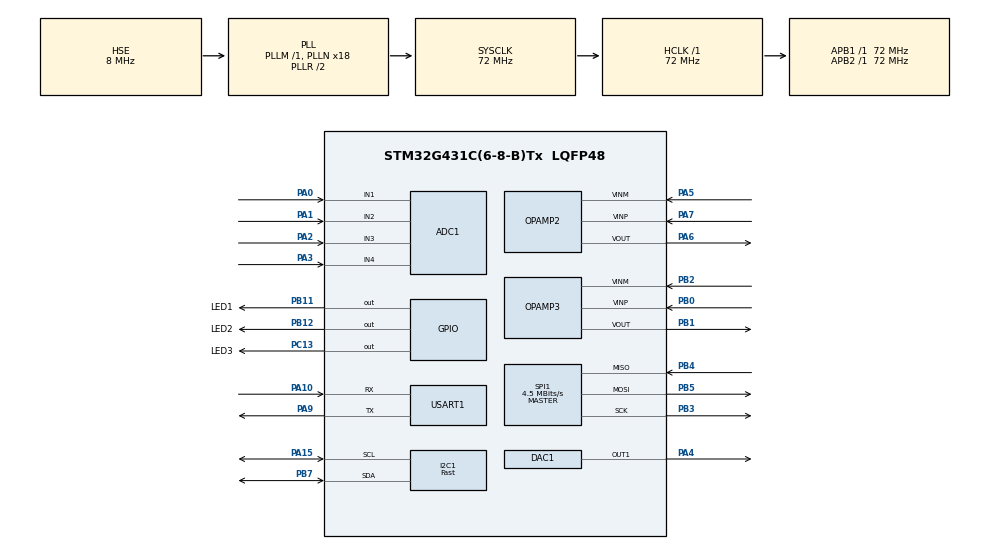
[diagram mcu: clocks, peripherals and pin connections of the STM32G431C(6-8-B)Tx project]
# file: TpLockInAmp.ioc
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ADC1.Channel-22\#ChannelRegularConversion=ADC_CHANNEL_2
ADC1.Channel-23\#ChannelRegularConversion=ADC_CHANNEL_3
ADC1.Channel-24\#ChannelRegularConversion=ADC_CHANNEL_4
ADC1.Channel-5\#ChannelRegularConversion=ADC_CHANNEL_1
ADC1.ClockPrescaler=ADC_CLOCK_ASYNC_DIV6
ADC1.ContinuousConvMode=DISABLE
ADC1.DMAContinuousRequests=ENABLE
ADC1.DiscontinuousConvMode=DISABLE
ADC1.EOCSelection=ADC_EOC_SINGLE_CONV
ADC1.ExternalTrigConv=ADC_EXTERNALTRIG_T2_TRGO
ADC1.ExternalTrigConvEdge=ADC_EXTERNALTRIGCONVEDGE_RISING
ADC1.NbrOfConversion=4
ADC1.NbrOfConversionFlag=1
ADC1.OffsetNumber-22\#ChannelRegularConversion=ADC_OFFSET_NONE
ADC1.OffsetNumber-23\#ChannelRegularConversion=ADC_OFFSET_NONE
ADC1.OffsetNumber-24\#ChannelRegularConversion=ADC_OFFSET_NONE
ADC1.OffsetNumber-5\#ChannelRegularConversion=ADC_OFFSET_NONE
ADC1.Rank-22\#ChannelRegularConversion=2
ADC1.Rank-23\#ChannelRegularConversion=3
ADC1.Rank-24\#ChannelRegularConversion=4
ADC1.Rank-5\#ChannelRegularConversion=1
ADC1.SamplingTime-22\#ChannelRegularConversion=ADC_SAMPLETIME_2CYCLES_5
ADC1.SamplingTime-23\#ChannelRegularConversion=ADC_SAMPLETIME_2CYCLES_5
ADC1.SamplingTime-24\#ChannelRegularConversion=ADC_SAMPLETIME_2CYCLES_5
ADC1.SamplingTime-5\#ChannelRegularConversion=ADC_SAMPLETIME_2CYCLES_5
ADC1.master=1
Dma.ADC1.0.Direction=DMA_PERIPH_TO_MEMORY
Dma.ADC1.0.EventEnable=DISABLE
Dma.ADC1.0.Instance=DMA1_Channel1
Dma.ADC1.0.MemDataAlignment=DMA_MDATAALIGN_HALFWORD
Dma.ADC1.0.MemInc=DMA_MINC_ENABLE
Dma.ADC1.0.Mode=DMA_CIRCULAR
Dma.ADC1.0.PeriphDataAlignment=DMA_PDATAALIGN_HALFWORD
Dma.ADC1.0.PeriphInc=DMA_PINC_DISABLE
Dma.ADC1.0.Polarity=HAL_DMAMUX_REQ_GEN_RISING
Dma.ADC1.0.Priority=DMA_PRIORITY_LOW
Dma.ADC1.0.RequestNumber=1
Dma.ADC1.0.SignalID=NONE
Dma.ADC1.0.SyncEnable=DISABLE
Dma.ADC1.0.SyncPolarity=HAL_DMAMUX_SYNC_NO_EVENT
Dma.ADC1.0.SyncRequestNumber=1
Dma.ADC1.0.SyncSignalID=NONE
Dma.Request0=ADC1
I2C1.I2C_Speed_Mode=I2C_Fast
I2C1.Timing=0x00702681
Mcu.Family=STM32G4
Mcu.Name=STM32G431C(6-8-B)Tx
Mcu.Package=LQFP48
NVIC.DMA1_Channel1_IRQn=true\:0\:0\:false\:false\:true\:false\:true
NVIC.PriorityGroup=NVIC_PRIORITYGROUP_4
NVIC.TIM2_IRQn=true\:0\:0\:false\:false\:true\:true\:true
NVIC.TIM6_DAC_IRQn=true\:0\:0\:false\:false\:true\:true\:true
NVIC.TIM7_IRQn=true\:0\:0\:false\:false\:true\:true\:true
NVIC.USART1_IRQn=true\:0\:0\:false\:false\:true\:true\:true
OPAMP2.PowerMode=OPAMP_POWERMODE_NORMALSPEED
OPAMP3.PowerMode=OPAMP_POWERMODE_NORMALSPEED
PA0.Mode=IN1-Single-Ended
PA0.Signal=ADC1_IN1
PA1.Mode=IN2-Single-Ended
PA1.Signal=ADC1_IN2
PA10.Mode=Asynchronous
PA10.Signal=USART1_RX
PA13.Mode=Serial_Wire
PA13.Signal=SYS_JTMS-SWDIO
PA14.Mode=Serial_Wire
PA14.Signal=SYS_JTCK-SWCLK
PA15.Mode=I2C
PA15.Signal=I2C1_SCL
PA2.Mode=IN3-Single-Ended
PA2.Signal=ADC1_IN3
PA3.Mode=IN4-Single-Ended
PA3.Signal=ADC1_IN4
PA4.Signal=COMP_DAC11_group
PA5.Mode=Standalone
PA5.Signal=OPAMP2_VINM
PA6.Mode=Standalone
PA6.Signal=OPAMP2_VOUT
PA7.Mode=Standalone
PA7.Signal=OPAMP2_VINP
PA9.Mode=Asynchronous
PA9.Signal=USART1_TX
PB0.Mode=Standalone
PB0.Signal=OPAMP3_VINP
PB1.Mode=Standalone
PB1.Signal=OPAMP3_VOUT
PB11.GPIO_Label=LED1
PB11.GPIO_PuPd=GPIO_PULLDOWN
PB11.PinState=GPIO_PIN_SET
PB11.Signal=GPIO_Output
PB12.GPIO_Label=LED2
PB12.GPIO_PuPd=GPIO_PULLDOWN
PB12.PinState=GPIO_PIN_SET
PB12.Signal=GPIO_Output
PB2.Mode=Standalone
PB2.Signal=OPAMP3_VINM
PB3.Mode=Full_Duplex_Master
PB3.Signal=SPI1_SCK
PB4.Mode=Full_Duplex_Master
PB4.Signal=SPI1_MISO
PB5.Mode=Full_Duplex_Master
PB5.Signal=SPI1_MOSI
PB7.Mode=I2C
PB7.Signal=I2C1_SDA
PC13.GPIO_Label=LED3
PC13.PinState=GPIO_PIN_SET
PC13.Signal=GPIO_Output
PF0-OSC_IN.Mode=HSE-External-Oscillator
PF0-OSC_IN.Signal=RCC_OSC_IN
PF1-OSC_OUT.Mode=HSE-External-Oscillator
PF1-OSC_OUT.Signal=RCC_OSC_OUT
ProjectManager.HeapSize=0x200
ProjectManager.StackSize=0x400
ProjectManager.TargetToolchain=MDK-ARM V5.32
RCC.ADC12Freq_Value=72000000
RCC.AHBFreq_Value=72000000
RCC.APB1Freq_Value=72000000
RCC.APB1TimFreq_Value=72000000
RCC.APB2Freq_Value=72000000
RCC.APB2TimFreq_Value=72000000
RCC.CortexFreq_Value=72000000
RCC.EXTERNAL_CLOCK_VALUE=12288000
RCC.HCLKFreq_Value=72000000
RCC.HSE_VALUE=8000000
RCC.HSI48_VALUE=48000000
RCC.HSI_VALUE=16000000
RCC.LSE_VALUE=32768
RCC.PLLN=18
RCC.PLLSourceVirtual=RCC_PLLSOURCE_HSE
RCC.SYSCLKFreq_VALUE=72000000
RCC.SYSCLKSource=RCC_SYSCLKSOURCE_PLLCLK
RCC.USBFreq_Value=72000000
RCC.VCOOutputFreq_Value=144000000
SH.COMP_DAC11_group.0=DAC1_OUT1,DAC_OUT1
SPI1.BaudRatePrescaler=SPI_BAUDRATEPRESCALER_16
SPI1.CLKPhase=SPI_PHASE_2EDGE
SPI1.CLKPolarity=SPI_POLARITY_HIGH
SPI1.CalculateBaudRate=4.5 MBits/s
SPI1.DataSize=SPI_DATASIZE_8BIT
SPI1.Direction=SPI_DIRECTION_2LINES
SPI1.Mode=SPI_MODE_MASTER
SPI1.VirtualType=VM_MASTER
TIM2.AutoReloadPreload=TIM_AUTORELOAD_PRELOAD_ENABLE
TIM2.ClockDivision=TIM_CLOCKDIVISION_DIV1
TIM2.Dithering=Disable
TIM2.PeriodNoDither=300000-1
TIM2.TIM_MasterOutputTrigger=TIM_TRGO_UPDATE
TIM2.TIM_MasterSlaveMode=TIM_MASTERSLAVEMODE_DISABLE
TIM6.AutoReloadPreload=TIM_AUTORELOAD_PRELOAD_ENABLE
TIM6.PeriodNoDither=300-1
TIM6.Prescaler=1000-1
TIM6.TIM_MasterOutputTrigger=TIM_TRGO_RESET
TIM7.AutoReloadPreload=TIM_AUTORELOAD_PRELOAD_ENABLE
TIM7.PeriodNoDither=7200-1
TIM7.Prescaler=10000-1
USART1.VirtualMode-Asynchronous=VM_ASYNC
VP_SYS_VS_DBSignals.Mode=DisableDeadBatterySignals
VP_TIM2_VS_ClockSourceINT.Mode=Internal
VP_TIM6_VS_ClockSourceINT.Mode=Enable_Timer
VP_TIM7_VS_ClockSourceINT.Mode=Enable_Timer
board=custom

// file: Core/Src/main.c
/* USER CODE BEGIN Header */
/**
  ******************************************************************************
  * @file           : main.c
  * @brief          : Main program body
  ******************************************************************************
  * @attention
  *
  * <h2><center>&copy; Copyright (c) 2022 STMicroelectronics.
  * All rights reserved.</center></h2>
  *
  * This software component is licensed by ST under BSD 3-Clause license,
  * the "License"; You may not use this file except in compliance with the
  * License. You may obtain a copy of the License at:
  *                        opensource.org/licenses/BSD-3-Clause
  *
  ******************************************************************************
  */
/* USER CODE END Header */
#include "main.h"
#include "adc.h"
#include "dac.h"
#include "dma.h"
#include "i2c.h"
#include "opamp.h"
#include "spi.h"
#include "tim.h"
#include "usart.h"
#include "gpio.h"

/* USER CODE BEGIN Includes */
#include "Usermain.h"
#include "string.h"
/* USER CODE END Includes */

/* USER CODE BEGIN PV */
uint8_t RxByte;
uint8_t RxBuff[1];
uint16_t Rx_Count;
/* USER CODE END PV */

void SystemClock_Config(void);

int main(void)
{

  /* MCU Configuration--------------------------------------------------------*/

  /* Reset of all peripherals, Initializes the Flash interface and the Systick. */
  HAL_Init();

  /* Configure the system clock */
  SystemClock_Config();

  /* Initialize all configured peripherals */
  MX_GPIO_Init();
  MX_DAC1_Init();
  MX_USART1_UART_Init();
  MX_I2C1_Init();
  MX_DMA_Init();
  MX_TIM6_Init();
  MX_ADC1_Init();
  MX_OPAMP2_Init();
  MX_OPAMP3_Init();
  MX_SPI1_Init();
  MX_TIM7_Init();
  MX_TIM2_Init();
  /* USER CODE BEGIN 2 */
	HAL_UART_Receive_IT(&huart1,RxBuff,1);
  /* USER CODE END 2 */

  /* Infinite loop */
  while (1)
  {

    /* USER CODE BEGIN 3 */
		Usermain();
  }
  /* USER CODE END 3 */
}

void SystemClock_Config(void)
{
  RCC_OscInitTypeDef RCC_OscInitStruct = {0};
  RCC_ClkInitTypeDef RCC_ClkInitStruct = {0};
  RCC_PeriphCLKInitTypeDef PeriphClkInit = {0};

  /** Configure the main internal regulator output voltage
  */
  HAL_PWREx_ControlVoltageScaling(PWR_REGULATOR_VOLTAGE_SCALE1);
  /** Initializes the RCC Oscillators according to the specified parameters
  * in the RCC_OscInitTypeDef structure.
  */
  RCC_OscInitStruct.OscillatorType = RCC_OSCILLATORTYPE_HSE;
  RCC_OscInitStruct.HSEState = RCC_HSE_ON;
  RCC_OscInitStruct.PLL.PLLState = RCC_PLL_ON;
  RCC_OscInitStruct.PLL.PLLSource = RCC_PLLSOURCE_HSE;
  RCC_OscInitStruct.PLL.PLLM = RCC_PLLM_DIV1;
  RCC_OscInitStruct.PLL.PLLN = 18;
  RCC_OscInitStruct.PLL.PLLP = RCC_PLLP_DIV2;
  RCC_OscInitStruct.PLL.PLLQ = RCC_PLLQ_DIV2;
  RCC_OscInitStruct.PLL.PLLR = RCC_PLLR_DIV2;
  if (HAL_RCC_OscConfig(&RCC_OscInitStruct) != HAL_OK)
  {
    Error_Handler();
  }
  /** Initializes the CPU, AHB and APB buses clocks
  */
  RCC_ClkInitStruct.ClockType = RCC_CLOCKTYPE_HCLK|RCC_CLOCKTYPE_SYSCLK
                              |RCC_CLOCKTYPE_PCLK1|RCC_CLOCKTYPE_PCLK2;
  RCC_ClkInitStruct.SYSCLKSource = RCC_SYSCLKSOURCE_PLLCLK;
  RCC_ClkInitStruct.AHBCLKDivider = RCC_SYSCLK_DIV1;
  RCC_ClkInitStruct.APB1CLKDivider = RCC_HCLK_DIV1;
  RCC_ClkInitStruct.APB2CLKDivider = RCC_HCLK_DIV1;

  if (HAL_RCC_ClockConfig(&RCC_ClkInitStruct, FLASH_LATENCY_2) != HAL_OK)
  {
    Error_Handler();
  }
  /** Initializes the peripherals clocks
  */
  PeriphClkInit.PeriphClockSelection = RCC_PERIPHCLK_USART1|RCC_PERIPHCLK_I2C1
                              |RCC_PERIPHCLK_ADC12;
  PeriphClkInit.Usart1ClockSelection = RCC_USART1CLKSOURCE_PCLK2;
  PeriphClkInit.I2c1ClockSelection = RCC_I2C1CLKSOURCE_PCLK1;
  PeriphClkInit.Adc12ClockSelection = RCC_ADC12CLKSOURCE_SYSCLK;
  if (HAL_RCCEx_PeriphCLKConfig(&PeriphClkInit) != HAL_OK)
  {
    Error_Handler();
  }
}

/* USER CODE BEGIN 4 */
void HAL_UART_RxCpltCallback(UART_HandleTypeDef *huart)
{
    if(huart->Instance == USART1)//判断串口号
    {
			if(RxBuff[0]  == 0x0A) HAL_NVIC_SystemReset();
			HAL_UART_Receive_IT(&huart1,RxBuff,1);
		}
}
/* USER CODE END 4 */

void Error_Handler(void)
{
  __disable_irq();
  while (1)
  {
  }
}

/************************ (C) COPYRIGHT STMicroelectronics *****END OF FILE****/
